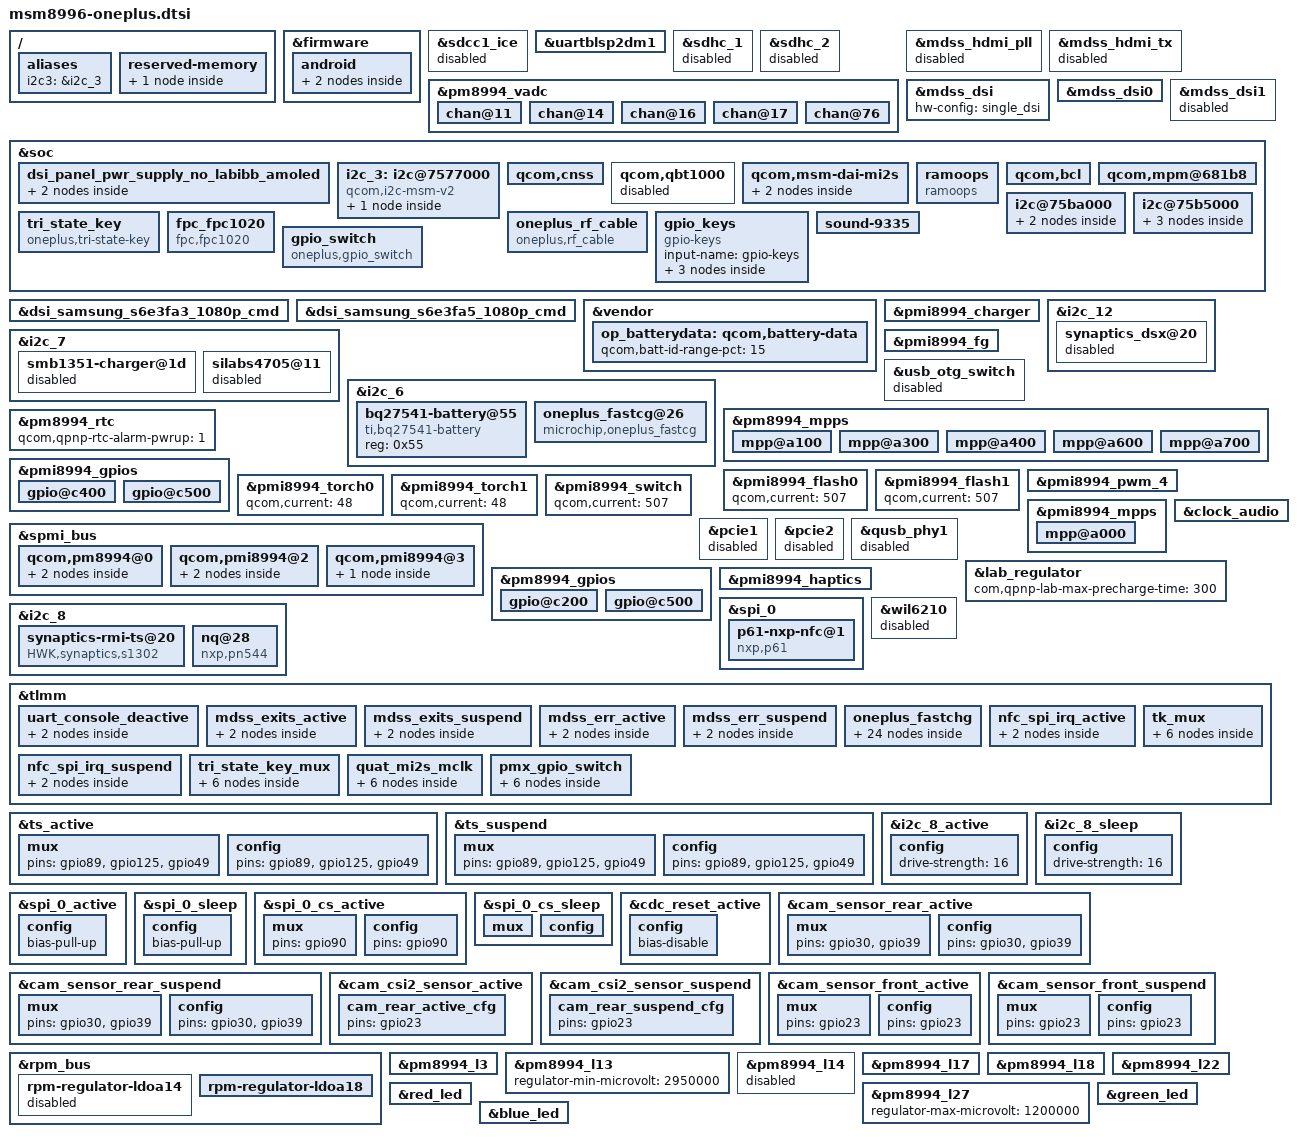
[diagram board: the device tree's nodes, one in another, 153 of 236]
/* Copyright (c) 2015-2016, The Linux Foundation. All rights reserved.
 *
 * This program is free software; you can redistribute it and/or modify
 * it under the terms of the GNU General Public License version 2 and
 * only version 2 as published by the Free Software Foundation.
 *
 * This program is distributed in the hope that it will be useful,
 * but WITHOUT ANY WARRANTY; without even the implied warranty of
 * MERCHANTABILITY or FITNESS FOR A PARTICULAR PURPOSE.  See the
 * GNU General Public License for more details.
 */

#include "dsi-panel-samsung-s6e3fa3-1080p-cmd.dtsi"
#include "dsi-panel-samsung-s6e3fa5-1080p-cmd.dtsi"

/ {
	aliases {
		i2c3 = &i2c_3;
	};

	reserved-memory {
		ramoops_mem: ramoops_region@ac000000 {
			compatible = "removed-dma-pool";
			no-map;
			reg = <0 0xAC000000 0 0x200000>;
		};
	};
};

&firmware {
	android {
		fstab {
			/delete-node/ vendor;
			system {
				compatible = "android,system";
				dev = "/dev/block/platform/soc/624000.ufshc/by-name/system";
				type = "ext4";
				mnt_flags = "ro,barrier=1,discard";
				fsmgr_flags = "wait,verify";
				status = "ok";
			};
		};
	};
};

&sdcc1_ice {
	status = "disabled";
};

&uartblsp2dm1 {
	status = "ok";
	pinctrl-names = "uart_active", "uart_deactive";
	pinctrl-0 = <&uart_console_active>;
	pinctrl-1 = <&uart_console_deactive>;
};

&sdhc_1 {
	status = "disabled";
};

&sdhc_2 {
	status = "disabled";
};

&pm8994_vadc {
	/* VADC Channel configuration */
	chan@11 {
		label = "rf_mpp2";
		reg = <0x11>;
		qcom,decimation = <0>;
		qcom,pre-div-channel-scaling = <0>;
		qcom,calibration-type = "absolute";
		qcom,scale-function = <0>;
		qcom,hw-settle-time = <0>;
		qcom,fast-avg-setup = <0>;
	};
	chan@14 {
		label = "rf_mpp5";
		reg = <0x14>;
		qcom,decimation = <0>;
		qcom,pre-div-channel-scaling = <0>;
		qcom,calibration-type = "absolute";
		qcom,scale-function = <0>;
		qcom,hw-settle-time = <0>;
		qcom,fast-avg-setup = <0>;
	};
	chan@16 {
		label = "id_ant_pcba_mpp7";
		reg = <0x16>;
		qcom,decimation = <0>;
		qcom,pre-div-channel-scaling = <0>;
		qcom,calibration-type = "absolute";
		qcom,scale-function = <0>;
		qcom,hw-settle-time = <0>;
		qcom,fast-avg-setup = <0>;
	};
	chan@17 {
		label = "rf_mpp8";
		reg = <0x17>;
		qcom,decimation = <0>;
		qcom,pre-div-channel-scaling = <0>;
		qcom,calibration-type = "absolute";
		qcom,scale-function = <0>;
		qcom,hw-settle-time = <0>;
		qcom,fast-avg-setup = <0>;
	};
	chan@76 {
		label = "pcb_version_AMUX_HW_ID";
		reg = <0x76>;
		qcom,decimation = <0>;
		qcom,pre-div-channel-scaling = <0>;
		qcom,calibration-type = "absolute";
		qcom,scale-function = <0>;
		qcom,hw-settle-time = <0>;
		qcom,fast-avg-setup = <0>;
	};
};

&mdss_hdmi_pll {
	status = "disabled";
};

&mdss_hdmi_tx {
	status = "disabled";
};

&mdss_dsi {
	hw-config = "single_dsi";
};

&mdss_dsi0 {
	qcom,dsi-pref-prim-pan = <&dsi_samsung_s6e3fa3_1080p_cmd>;
	pinctrl-names = "mdss_default", "mdss_sleep";
	pinctrl-0 = <&mdss_dsi_active &mdss_te_active &mdss_exits_active &mdss_err_active>;
	pinctrl-1 = <&mdss_dsi_suspend &mdss_te_suspend &mdss_exits_suspend &mdss_err_suspend>;
	qcom,platform-te-gpio = <&tlmm 11 0>;
	qcom,platform-reset-gpio = <&tlmm 8 0>;
	qcom,lcd-vddi-en-gpio = <&tlmm 26 0>;
	oled-vdda-supply = <&pm8994_s5>;
	vddio-supply = <&pm8994_l18>;
	/delete-property/ qcom,platform-reset-gpio;
	/delete-property/ qcom,platform-bklight-en-gpio;
	/delete-property/ lab-supply;
	/delete-property/ ibb-supply;
};

&mdss_dsi1 {
	status = "disabled";
};

&soc {
	dsi_panel_pwr_supply_no_labibb_amoled: dsi_panel_pwr_supply_no_labibb_amoled {
		#address-cells = <1>;
		#size-cells = <0>;

		qcom,panel-supply-entry@0 {
			reg = <0>;
			qcom,supply-name = "vddio";
			qcom,supply-min-voltage = <3300000>;
			qcom,supply-max-voltage = <3300000>;
			qcom,supply-enable-load = <62000>;
			qcom,supply-disable-load = <80>;
		};

		qcom,panel-supply-entry@1 {
			reg = <1>;
			qcom,supply-name = "oled-vdda";
			qcom,supply-min-voltage = <2150000>;
			qcom,supply-max-voltage = <2150000>;
			qcom,supply-enable-load = <62000>;
			qcom,supply-disable-load = <0>;
		};
	};
};

&dsi_samsung_s6e3fa3_1080p_cmd {
	qcom,mdss-dsi-panel-timings-phy-v2 = [
		24 1F 08 09 05 03 04 a0
		24 1F 08 09 05 03 04 a0
		24 1F 08 09 05 03 04 a0
		24 1F 08 09 05 03 04 a0
		24 1B 08 09 05 03 04 a0
	];
	qcom,cont-splash-enabled;
	qcom,panel-supply-entries = <&dsi_panel_pwr_supply_no_labibb_amoled>;
	qcom,esd-check-enabled;
	qcom,mdss-dsi-panel-status-check-mode = "te_signal_check";
	qcom,ulps-enabled;
	qcom,panel-allow-phy-poweroff;
};

&dsi_samsung_s6e3fa5_1080p_cmd {
       qcom,mdss-dsi-panel-timings-phy-v2  = [
		24 1F 08 09 05 03 04 a0
		24 1F 08 09 05 03 04 a0
		24 1F 08 09 05 03 04 a0
		24 1F 08 09 05 03 04 a0
		24 1B 08 09 05 03 04 a0
	];
	qcom,cont-splash-enabled;
	qcom,panel-supply-entries = <&dsi_panel_pwr_supply_no_labibb_amoled>;
	qcom,esd-check-enabled;
	qcom,mdss-dsi-panel-status-check-mode = "te_signal_check";
	qcom,ulps-enabled;
	qcom,panel-allow-phy-poweroff;
};

&vendor {
	op_batterydata: qcom,battery-data {
		qcom,batt-id-range-pct = <15>;
		#include "batterydata-op-3000mah.dtsi"
		#include "batterydata-op-3400mah.dtsi"
	};
};

&pmi8994_charger {
	qcom,iterm-ma = <200>;
	qcom,float-voltage-mv = <4320>;
	qcom,override-usb-current;
	/* ibatmax setting for different temp regions */
	qcom,ibatmax-little-cold-ma = <300>;
	qcom,ibatmax-cool-ma = <400>;
	qcom,ibatmax-little-cool-ma = <700>;
	qcom,ibatmax-pre-normal-ma = <1200>;
	qcom,ibatmax-normal-ma = <1910>;
	qcom,ibatmax-warm-ma = <700>;
	/* vbatmax setting for different temp regions */
	qcom,vbatmax-little-cold-mv = <3980>;
	qcom,vbatmax-cool-mv = <4320>;
	qcom,vbatmax-little-cool-mv = <4320>;
	qcom,vbatmax-pre-normal-mv = <4320>;
	qcom,vbatmax-normal-mv = <4320>;
	qcom,vbatmax-warm-mv = <4080>;
	/* vbatdet setting for different temp regions */
	qcom,vbatdet-little-cold-mv = <3700>;
	qcom,vbatdet-cool-mv = <4100>;
	qcom,vbatdet-little-cool-mv = <4220>;
	qcom,vbatdet-pre-normal-mv = <4220>;
	qcom,vbatdet-normal-mv = <4220>;
	qcom,vbatdet-warm-mv = <4000>;
	/* vbatdet setting for different temp regions */
	qcom,cold-bat-decidegc = <30>;
	qcom,little-cold-bat-decidegc = <0>;
	qcom,cool-bat-decidegc = <50>;
	qcom,little-cool-bat-decidegc = <120>;
	qcom,pre-normal-bat-decidegc = <160>;
	qcom,warm-bat-decidegc = <450>;
	qcom,hot-bat-decidegc = <530>;
	qcom,cutoff-voltage-with-charger=<3250>;
	qcom,thermal-mitigation = <2000 1300 1200 1200>;
};

&i2c_7 {
	smb1351-charger@1d {
		status = "disabled";
	};
};

&i2c_12 {
	synaptics_dsx@20 {
		status = "disabled"; 
	};
};

&i2c_6 {
	qcom,clk-freq-out = <100000>;
	qcom,fs-clk-div =<104>;
	qcom,high-time-clk-div=<82>;
	bq27541-battery@55 {
		status = "ok";
		compatible = "ti,bq27541-battery";
		reg = <0x55>;
	};
	oneplus_fastcg@26{
		status = "ok";
		compatible = "microchip,oneplus_fastcg";
		reg = <0x26>;
		microchip,mcu-en-gpio = <&tlmm 119 0x00>;
		microchip,usb-sw-gpio = <&tlmm 135 0x00>;
		microchip,ap-clk = <&tlmm 75 0x00>;
		microchip,ap-data = <&tlmm 74 0x00>;
		pinctrl-names = "mux_fastchg_active",
				"mux_fastchg_suspend",
				"mcu_data_active",
				"mcu_data_suspend";
		pinctrl-0 = <&fastchg_active
		&usb_sw_active
		&ap_clk_active >;
		pinctrl-1 = <&usb_sw_suspend
		&fastchg_suspend
		&ap_clk_suspend>;
		pinctrl-2 =<&ap_data_active>;
		pinctrl-3 =<&ap_data_suspend>;
		clocks = <&clock_gcc clk_uart_snoc_msmbus_a_clk>,
			 <&clock_gcc clk_uart_cnoc_msmbus_a_clk>;
		clock-names = "snoc", "cnoc";

	};
};

&pmi8994_fg {
	qcom,battery-data = <&op_batterydata>;
	/delete-property/ qcom,ext-sense-type;
	qcom,resume-soc = <99>;
	qcom,fg-iterm-ma = <200>;
	qcom,fg-chg-iterm-ma = <165>;
	qcom,fg-cc-cv-threshold-mv = <4310>;
	qcom,fg-cutoff-voltage-mv=<3200>;
	oem,use_external_fg;
};

&usb_otg_switch {
	status = "disabled";
};

&pm8994_mpps {
	mpp@a100 { /* MPP 2 */
		qcom,mode = <4>; /* AIN input */
		qcom,ain-route = <1>; /* AMUX 6 ,QPNP_PIN_AIN_AMUX_CH6   = 1*/
		qcom,master-en = <1>; /* Enable MPP */
		qcom,src-sel = <0>; /* Function constant */
		/delete-property/ status;
	};

	mpp@a300 { /* MPP 4 */
		qcom,mode = <4>; /* AIN input */
		qcom,invert = <1>; /* Enable MPP */
		qcom,ain-route = <3>; /* AMUX 8 */
		qcom,master-en = <1>;
		qcom,src-sel = <0>; /* Function constant */
	};

	mpp@a400 { /* MPP 5 */
		qcom,mode = <4>; /* AIN input */
		qcom,ain-route = <0>; /* AMUX 5 ,QPNP_PIN_AIN_AMUX_CH5   = 0*/
		qcom,master-en = <1>; /* Enable MPP */
		qcom,src-sel = <0>; /* Function constant */
		/delete-property/ status;
	};

	mpp@a600 { /* MPP 7 */
		qcom,mode = <4>; /* AIN input */
		qcom,ain-route = <2>; /* AMUX 7 ,QPNP_PIN_AIN_AMUX_CH7   = 2*/
		qcom,master-en = <1>; /* Enable MPP */
		qcom,src-sel = <0>; /* Function constant */
		/delete-property/ status;
	};

	mpp@a700 { /* MPP 8 */
		qcom,mode = <4>; /* AIN input */
		qcom,ain-route = <3>; /* AMUX 6 ,QPNP_PIN_AIN_AMUX_CH8   = 3*/
		qcom,master-en = <1>; /* Enable MPP */
		qcom,src-sel = <0>; /* Function constant */
		/delete-property/ status;
	};
};

&pm8994_rtc {
	qcom,qpnp-rtc-alarm-pwrup = <1>;
};

&pmi8994_gpios {
	gpio@c400 {//pmi8996 gpio 5 type-c IC INT pin
		qcom,mode = <0>;
		qcom,pull = <5>;
		qcom,vin-sel = <2>;
		qcom,src-sel = <0>;
		qcom,master-en = <1>;
		status = "okay";

	};

	gpio@c500 {//pmi8996 gpio 6 type-c IC OTG_USB_ID pin
		qcom,mode = <0>;
		qcom,pull = <5>;
		qcom,vin-sel = <2>;
		qcom,src-sel = <0>;
		qcom,master-en = <1>;
		status = "okay";
	};
};

&pmi8994_flash0 {
	qcom,current = <507>;
};

&pmi8994_flash1 {
	qcom,current = <507>;
};

&pmi8994_pwm_4 {
	qcom,channel-owner = "lcd_bl";
	qcom,dtest-line = <4>;
	qcom,dtest-output = <1>;
	status = "okay";
};

&pmi8994_torch0 {
	qcom,current = <48>;
};

&pmi8994_torch1 {
	qcom,current = <48>;
};

&pmi8994_switch {
	qcom,current = <507>;
};

&pmi8994_mpps {
	mpp@a000 { /* MPP 1 */
		qcom,mode = <1>;                /* Digital output */
		qcom,output-type = <0>;         /* CMOS logic */
		qcom,vin-sel = <2>;             /* S4 1.8V */
		qcom,src-sel = <7>;             /* DTEST4 */
		qcom,master-en = <1>;           /* Enable MPP */
		status = "okay";
	};
	/delete-node/ mpp@a300;
};

&soc {
	i2c_3: i2c@7577000 { /* BLSP2 QUP1 */
			compatible = "qcom,i2c-msm-v2";
			#address-cells = <1>;
			#size-cells = <0>;
			reg-names = "qup_phys_addr";
			reg = <0x7577000 0x1000>;
			interrupt-names = "qup_irq";
			interrupts = <0 97 0>;
			dmas = <&dma_blsp1 16 32 0x20000020 0x20>,
			<&dma_blsp1 17 32 0x20000020 0x20>;
			dma-names = "tx", "rx";
			qcom,master-id = <86>;
			qcom,clk-freq-out = <100000>;
			qcom,clk-freq-in = <19200000>;
			qcom,fs-clk-div =<104>;
			qcom,high-time-clk-div=<82>;
			clock-names = "iface_clk", "core_clk";
			clocks = <&clock_gcc clk_gcc_blsp1_ahb_clk>,
			<&clock_gcc clk_gcc_blsp1_qup3_i2c_apps_clk>;
			pinctrl-names = "i2c_active", "i2c_sleep";
			pinctrl-0 = <&i2c_3_active>;
			pinctrl-1 = <&i2c_3_sleep>;
	};

	qcom,cnss {
		/delete-property/ wlan-ant-switch-supply;
	};

	qcom,qbt1000 {
		status = "disabled";
	};

	qcom,msm-dai-mi2s {
		/delete-node/ qcom,msm-dai-q6-mi2s-tert;
		/delete-node/ qcom,msm-dai-q6-mi2s-quat;
		dai_tert_mi2s: qcom,msm-dai-q6-mi2s-tert {
				compatible = "qcom,msm-dai-q6-mi2s";
				qcom,msm-dai-q6-mi2s-dev-id = <2>;
				qcom,msm-mi2s-rx-lines = <2>;
				qcom,msm-mi2s-tx-lines = <1>;
				pinctrl-names = "default", "sleep";
		};

		dai_quat_mi2s: qcom,msm-dai-q6-mi2s-quat {
			compatible = "qcom,msm-dai-q6-mi2s";
			qcom,msm-dai-q6-mi2s-dev-id = <3>;
			qcom,msm-mi2s-rx-lines = <1>; /* SD0 (1 << 0) */
			qcom,msm-mi2s-tx-lines = <2>; /* SD1 (1 << 1) */
			qcom,msm-mi2s-slave = <0>;
			qcom,msm-mi2s-ext-mclk = <0>;
			pinctrl-names = "default", "sleep";

			pinctrl-0 = <&quat_mi2s_active  &quat_mi2s_sd0_active &quat_mi2s_sd1_active >;
			pinctrl-1 = <&quat_mi2s_sleep  &quat_mi2s_sd0_sleep &quat_mi2s_sd1_sleep >;
		};
	};

	ramoops {
		compatible = "ramoops";
		memory-region = <&ramoops_mem>;
		record-size = <0x0 0x20000>;
		console-size = <0x0 0x100000>;
		pmsg-size = <0x0 0x80000>;
	};

	qcom,bcl {
		/delete-property/ qcom,bcl-hotplug-list;
		/delete-property/ qcom,bcl-soc-hotplug-list;
	};

	qcom,mpm@681b8 {
		qcom,gic-map = <2 216>, /* tsens_upper_lower_int */
			<79 379>,   /* qusb2phy_dmse_hv_prim */
			<80 384>,   /* qusb2phy_dmse_hv_sec */
			<81 379>,   /* qusb2phy_dpse_hv_prim */
			<82 384>,   /* qusb2phy_dpse_hv_sec */
			<52 275>,   /* qmp_usb3_lfps_rxterm_irq */
			<87 358>,   /* ee0_krait_hlos_spmi_periph_irq */
			<0xff 16>,  /* APCj_qgicdrCpu0HwFaultIrptReq */
			<0xff 23>,  /* APCj_qgicdrCpu0PerfMonIrptReq */
			<0xff 27>,  /* APCj_qgicdrCpu0QTmrVirtIrptReq */
			<0xff 32>,  /* APCj_qgicdrL2PerfMonIrptReq */
			<0xff 33>,  /* APCC_qgicL2PerfMonIrptReq */
			<0xff 34>,  /* APCC_qgicL2ErrorIrptReq */
			<0xff 35>,  /* WDT_barkInt */
			<0xff 40>,  /* qtimer_phy_irq */
			<0xff 41>,  /* APCj_qgicdrL2HwFaultNonFatalIrptReq */
			<0xff 42>,  /* APCj_qgicdrL2HwFaultFatalIrptReq */
			<0xff 49>,  /* L3UX_qgicL3ErrorIrptReq */
			<0xff 54>,  /* M4M_sysErrorInterrupt */
			<0xff 55>,  /* M4M_sysDlmInterrupt */
			<0xff 57>,  /* mss_to_apps_irq(0) */
			<0xff 58>,  /* mss_to_apps_irq(1) */
			<0xff 59>,  /* mss_to_apps_irq(2) */
			<0xff 60>,  /* mss_to_apps_irq(3) */
			<0xff 61>,  /* mss_a2_bam_irq */
			<0xff 62>,  /* QTMR_qgicFrm0VirtIrq */
			<0xff 63>,  /* QTMR_qgicFrm1PhysIrq */
			<0xff 64>,  /* QTMR_qgicFrm2PhysIrq */
			<0xff 65>,  /* QTMR_qgicFrm3PhysIrq */
			<0xff 66>,  /* QTMR_qgicFrm4PhysIrq */
			<0xff 67>,  /* QTMR_qgicFrm5PhysIrq */
			<0xff 68>,  /* QTMR_qgicFrm6PhysIrq */
			<0xff 69>,  /* QTMR_qgicFrm7PhysIrq */
			<0xff 70>,  /* iommu_pmon_nonsecure_irq */
			<0xff 74>,  /* osmmu_CIrpt[1] */
			<0xff 75>,  /* osmmu_CIrpt[0] */
			<0xff 77>,  /* osmmu_CIrpt[0] */
			<0xff 78>,  /* osmmu_CIrpt[0] */
			<0xff 79>,  /* osmmu_CIrpt[0] */
			<0xff 80>,  /* CPR3_irq */
			<0xff 94>,  /* osmmu_CIrpt[0] */
			<0xff 97>,  /* iommu_nonsecure_irq */
			<0xff 99>,  /* msm_iommu_pmon_nonsecure_irq */
			<0xff 101>, /* camss_jpeg_mmu_cirpt */
			<0xff 102>, /* osmmu_CIrpt[1] */
			<0xff 105>, /* iommu_pmon_nonsecure_irq */
			<0xff 108>, /* osmmu_PMIrpt */
			<0xff 109>, /* ocmem_dm_nonsec_irq */
			<0xff 110>, /* csiphy_0_irq */
			<0xff 111>, /* csiphy_1_irq */
			<0xff 112>, /* csiphy_2_irq */
			<0xff 115>, /* mdss_irq */
			<0xff 126>, /* bam_irq[0] */
			<0xff 127>, /* blsp1_qup_irq(0) */
			<0xff 129>,
			<0xff 132>, /* blsp1_qup_irq(5) */
			<0xff 133>, /* blsp2_qup_irq(0) */
			<0xff 134>, /* blsp2_qup_irq(1) */
			<0xff 135>, /* blsp2_qup_irq(2) */
			<0xff 138>, /* blsp2_qup_irq(5) */
			<0xff 140>, /* blsp1_uart_irq(1) */
			<0xff 146>, /* blsp2_uart_irq(1) */
			<0xff 155>, /* sdcc_irq[0] */
			<0xff 157>, /* sdc2_irq[0] */
			<0xff 163>, /* usb30_ee1_irq */
			<0xff 164>, /* usb30_bam_irq(0) */
			<0xff 165>, /* usb30_hs_phy_irq */
			<0xff 166>, /* sdc1_pwr_cmd_irq */
			<0xff 170>, /* sdcc_pwr_cmd_irq */
			<0xff 171>, /* usb20_hs_phy_irq */
			<0xff 172>, /* usb20_power_event_irq */
			<0xff 173>, /* sdc1_irq[0] */
			<0xff 174>, /* o_wcss_apss_smd_med */
			<0xff 175>, /* o_wcss_apss_smd_low */
			<0xff 176>, /* o_wcss_apss_smsm_irq */
			<0xff 177>, /* o_wcss_apss_wlan_data_xfer_done */
			<0xff 178>, /* o_wcss_apss_wlan_rx_data_avail */
			<0xff 179>, /* o_wcss_apss_asic_intr */
			<0xff 180>, /* pcie20_2_int_pls_err */
			<0xff 181>, /* wcnss watchdog */
			<0xff 188>, /* lpass_irq_out_apcs(0) */
			<0xff 189>, /* lpass_irq_out_apcs(1) */
			<0xff 190>, /* lpass_irq_out_apcs(2) */
			<0xff 191>, /* lpass_irq_out_apcs(3) */
			<0xff 192>, /* lpass_irq_out_apcs(4) */
			<0xff 193>, /* lpass_irq_out_apcs(5) */
			<0xff 194>, /* lpass_irq_out_apcs(6) */
			<0xff 195>, /* lpass_irq_out_apcs(7) */
			<0xff 196>, /* lpass_irq_out_apcs(8) */
			<0xff 197>, /* lpass_irq_out_apcs(9) */
			<0xff 198>, /* coresight-tmc-etr interrupt */
			<0xff 200>, /* rpm_ipc(4) */
			<0xff 201>, /* rpm_ipc(5) */
			<0xff 202>, /* rpm_ipc(6) */
			<0xff 203>, /* rpm_ipc(7) */
			<0xff 204>, /* rpm_ipc(24) */
			<0xff 205>, /* rpm_ipc(25) */
			<0xff 206>, /* rpm_ipc(26) */
			<0xff 207>, /* rpm_ipc(27) */
			<0xff 208>,
			<0xff 210>,
			<0xff 211>, /* usb_dwc3_otg */
			<0xff 212>, /* usb30_power_event_irq */
			<0xff 215>, /* o_bimc_intr(0) */
			<0xff 224>, /* spdm_realtime_irq[1] */
			<0xff 238>, /* crypto_bam_irq[0] */
			<0xff 240>, /* summary_irq_kpss */
			<0xff 253>, /* sdc2_pwr_cmd_irq */
			<0xff 258>, /* lpass_irq_out_apcs[21] */
			<0xff 268>, /* bam_irq[1] */
			<0xff 270>, /* bam_irq[0] */
			<0xff 271>, /* bam_irq[0] */
			<0xff 276>, /* wlan_pci */
			<0xff 283>, /* pcie20_0_int_pls_err */
			<0xff 284>, /* pcie20_0_int_aer_legacy */
			<0xff 286>, /* pcie20_0_int_pls_link_down */
			<0xff 290>, /* ufs_ice_nonsec_level_irq */
			<0xff 293>, /* pcie20_2_int_pls_link_down */
			<0xff 295>, /* camss_cpp_mmu_cirpt[0] */
			<0xff 296>, /* camss_cpp_mmu_pmirpt */
			<0xff 297>, /* ufs_intrq */
			<0xff 298>, /* camss_cpp_mmu_cirpt */
			<0xff 302>, /* qdss_etrbytecnt_irq */
			<0xff 310>, /* pcie20_1_int_pls_err */
			<0xff 311>, /* pcie20_1_int_aer_legacy */
			<0xff 313>, /* pcie20_1_int_pls_link_down */
			<0xff 318>, /* venus0_mmu_pmirpt */
			<0xff 319>, /* venus0_irq */
			<0xff 325>, /* camss_irq18 */
			<0xff 326>, /* camss_irq0 */
			<0xff 327>, /* camss_irq1 */
			<0xff 328>, /* camss_irq2 */
			<0xff 329>, /* camss_irq3 */
			<0xff 330>, /* camss_irq4 */
			<0xff 331>, /* camss_irq5 */
			<0xff 332>, /* sps */
			<0xff 336>,
			<0xff 341>, /* camss_irq6 */
			<0xff 346>, /* camss_irq8 */
			<0xff 347>, /* camss_irq9 */
			<0xff 348>,
			<0xff 352>, /* mdss_mmu_cirpt[0] */
			<0xff 353>, /* mdss_mmu_cirpt[1] */
			<0xff 361>, /* ogpu_mmu_cirpt[0] */
			<0xff 362>, /* ogpu_mmu_cirpt[1] */
			<0xff 365>, /* ipa_irq[0] */
			<0xff 366>, /* ogpu_mmu_pmirpt */
			<0xff 367>, /* venus0_mmu_cirpt[0] */
			<0xff 368>, /* venus0_mmu_cirpt[1] */
			<0xff 369>, /* venus0_mmu_cirpt[2] */
			<0xff 370>, /* venus0_mmu_cirpt[3] */
			<0xff 375>, /* camss_vfe_mmu_cirpt[0] */
			<0xff 376>, /* camss_vfe_mmu_cirpt[1] */
			<0xff 380>, /* mdss_dma_mmu_cirpt[0] */
			<0xff 381>, /* mdss_dma_mmu_cirpt[1] */
			<0xff 385>, /* mdss_dma_mmu_pmirpt */
			<0xff 387>, /* osmmu_CIrpt[0] */
			<0xff 394>, /* osmmu_PMIrpt */
			<0xff 403>, /* osmmu_PMIrpt */
			<0xff 405>, /* osmmu_CIrpt[0] */
			<0xff 413>, /* osmmu_PMIrpt */
			<0xff 422>, /* ssc_irq_out_apcs[5] */
			<0xff 424>, /* ipa_irq[2] */
			<0xff 425>, /* lpass_irq_out_apcs[22] */
			<0xff 426>, /* lpass_irq_out_apcs[23] */
			<0xff 427>, /* lpass_irq_out_apcs[24] */
			<0xff 428>, /* lpass_irq_out_apcs[25] */
			<0xff 429>, /* lpass_irq_out_apcs[26] */
			<0xff 430>, /* lpass_irq_out_apcs[27] */
			<0xff 431>, /* lpass_irq_out_apcs[28] */
			<0xff 432>, /* lpass_irq_out_apcs[29] */
			<0xff 436>, /* lpass_irq_out_apcs[37] */
			<0xff 437>, /* pcie20_0_int_msi_dev0 */
			<0xff 445>, /* pcie20_1_int_msi_dev0 */
			<0xff 453>, /* pcie20_2_int_msi_dev0 */
			<0xff 461>, /* o_vmem_nonsec_irq */
			<0xff 462>, /* tsens1_tsens_critical_int */
			<0xff 464>, /* ipa_bam_irq[0] */
			<0xff 465>, /* ipa_bam_irq[2] */
			<0xff 477>, /* tsens0_tsens_critical_int */
			<0xff 480>, /* q6_wdog_expired_irq */
			<0xff 481>, /* mss_ipc_out_irq(4) */
			<0xff 483>, /* mss_ipc_out_irq(6) */
			<0xff 484>, /* mss_ipc_out_irq(7) */
			<0xff 487>, /* mss_ipc_out_irq(30) */
			<0xff 490>, /* tsens0_tsens_upper_lower_int */
			<0xff 493>; /* sdc1_ice_nonsec_level_irq */
		qcom,gpio-map = <3  1>,
			<4  5>,
			<5  9>,
			<6  11>,
			<7  66>,
			<8  22>,
			<9  24>,
			<10  26>,
			<11  34>,
			<12  36>,
			<13  37>, /* PCIe0 */
			<14  38>,
			<15  40>,
			<16  42>,
			<17  46>,
			<18  50>,
			<19  53>,
			<20  54>,
			<21  56>,
			<22  57>,
			<23  58>,
			<24  59>,
			<25  60>,
			<26  61>,
			<27  62>,
			<28  63>,
			<29  64>,
			<30  71>,
			<31  73>,
			<0xff  74>,
			<32  77>,
			<33  78>,
			<34  79>,
			<35  80>,
			<36  82>,
			<37  86>,
			<38  91>,
			<39  92>,
			<40  95>,
			<41  97>,
			<42  101>,
			<43  104>,
			<44  106>,
			<45  108>,
			<46  112>,
			<47  113>,
			<48  110>,
			<50  127>,
			<51  115>,
			<54  116>, /* PCIe2 */
			<55  117>,
			<56  118>,
			<57  119>,
			<58  120>,
			<59  121>,
			<60  122>,
			<61  123>,
			<62  124>,
			<63  125>,
			<64  126>,
			<65  129>,
			<66  131>,
			<67  132>, /* PCIe1 */
			<68  133>,
			<69  145>;
	};

	i2c@75ba000 {
		synaptics@20 {
			status = "disabled";
		};
		synaptics-rmi-ts@20 {
			compatible = "synaptics,s3320";
			reg = <0x20>;
			interrupt-parent = <&tlmm>;
			interrupts = <125 0x2008>;
			synaptics,irq-gpio = <&tlmm 125 0x2008>;
			synaptics,reset-gpio = <&tlmm 89 0x00>;
			synaptics,1v8-gpio = <&tlmm 49 0x00>;
			synaptics,tx-rx-num = <16 28>;
			synaptics,display-coords = <1080 1920>;
			vdd_2v8-supply = <&pm8994_l22>;
			vcc_i2c_1v8-supply = <&pm8994_s4>;
			oem,support_hw_poweroff;
			pinctrl-names = "pmx_ts_active", "pmx_ts_suspend";
			pinctrl-0 = <&ts_active>;
			pinctrl-1 = <&ts_suspend>;
		};
	};

	i2c@75b5000 {
		fusb301@21 {
			compatible = "fusb301";
			reg = <0x21>;
			fusb301,ID-gpio = <&pmi8994_gpios 6 0>;
			fusb301,irq-gpio = <&pmi8994_gpios 5 0>;
			// Underlying clocks used by secure touch
			clock-names = "iface_clk", "core_clk";
			clocks = <&clock_gcc clk_gcc_blsp2_ahb_clk>,
				 <&clock_gcc clk_gcc_blsp2_qup1_i2c_apps_clk>;
		};
		tusb320@60 {
			compatible = "tusb320";
			reg = <0x60>;
			tusb320,ID-gpio = <&pmi8994_gpios 6 0>;
			tusb320,irq-gpio = <&pmi8994_gpios 5 0>;
			// Underlying clocks used by secure touch
			clock-names = "iface_clk", "core_clk";
			clocks = <&clock_gcc clk_gcc_blsp2_ahb_clk>,
				 <&clock_gcc clk_gcc_blsp2_qup1_i2c_apps_clk>;
		};

		ptn5150@1d {
			compatible = "ptn5150";
			reg = <0x1d>;
			ptn5150,ID-gpio = <&pmi8994_gpios 6 0>;
			ptn5150,irq-gpio = <&pmi8994_gpios 5 0>;
			// Underlying clocks used by secure touch
			clock-names = "iface_clk", "core_clk";
			clocks = <&clock_gcc clk_gcc_blsp2_ahb_clk>,
				 <&clock_gcc clk_gcc_blsp2_qup1_i2c_apps_clk>;
		};

	};

	tri_state_key {
		compatible = "oneplus,tri-state-key";
		interrupt-parent = <&tlmm>;
		tristate,gpio_key2 = <&pm8994_gpios 4 0>;
		tristate,gpio_key1 = <&pm8994_gpios 6 0>;
		tristate,gpio_key3 = <&pm8994_gpios 5 0>;

		#pinctrl-names = "pmx_tri_state_key_active", "pmx_tri_state_key_suspend";
		#pinctrl-0 = <&tri_state_key_active>;
		#pinctrl-1 = <&tri_state_key_suspend>;
	};

	fpc_fpc1020 {
		compatible = "fpc,fpc1020";
		interrupt-parent = <&tlmm>;
		fpc,reset-gpio    = <&tlmm 86 0>;
		fpc,irq-gpio    = <&tlmm 95 0>;
		fpc,gpio_id0    = <&tlmm 25 0>;
		fpc,gpio_id1    = <&tlmm 143 0>;
		fpc,gpio_1V8_EN = <&tlmm 14 0x00>;
		#vcc_spi-supply  = <&pm8994_l13>;
		#vdd_ana-supply  = <&pm8994_l13>;
		#vdd_io-supply   = <&pm8994_s4>;

		#pinctrl-names = "pmx_tri_state_key_active", "pmx_tri_state_key_suspend";
		#pinctrl-0 = <&tri_state_key_active>;
		#pinctrl-1 = <&tri_state_key_suspend>;
	};

	oneplus_rf_cable {
		compatible = "oneplus,rf_cable";
		interrupt-parent = <&tlmm>;
		rf,cable-gpio    = <&tlmm 131 0>;

		#pinctrl-names = "pmx_tri_state_key_active", "pmx_tri_state_key_suspend";
		#pinctrl-0 = <&tri_state_key_active>;
		#pinctrl-1 = <&tri_state_key_suspend>;
	};

	i2c@7577000{
		status = "ok";
		test_tfa9890: tfa9890@36 {
			compatible = "nxp,tfa9890";
			reg = <0x36>;
			reset_gpio= <&tlmm 16 0>;
			status = "okay";
		};
	};

	gpio_keys {
		compatible = "gpio-keys";
		input-name = "gpio-keys";

		vol_up {
			label = "volume_up";
			gpios = <&pm8994_gpios 3 0x1>;
			linux,input-type = <1>;
			linux,code = <115>;
			debounce-interval = <15>;
		};

		/delete-node/ cam_snapshot;
		/delete-node/ cam_focus;

		vol_down {
			label = "volume_down";
			gpios = <&pm8994_gpios 2 0x1>;
			linux,input-type = <1>;
			linux,code = <114>;
			debounce-interval = <15>;
		};

		hallsensor_key {
			label = "hallsensor_key";
			gpios = <&tlmm 124 1>;
			interrupt-parent = <&tlmm>;
			interrupts = <124 0x0>;
			linux,input-type = <5>;
			linux,code = <0>;
			gpio-key,wakeup;
			debounce-interval = <15>;
		};
	};

	sound-9335 {
		qcom,model = "msm8996-tasha-mtp-snd-card";

		qcom,audio-routing =
			"AIF4 VI", "MCLK",
			"RX_BIAS", "MCLK",
			"MADINPUT", "MCLK",
			"hifi amp", "LINEOUT1",
			"hifi amp", "LINEOUT2",
			"AMIC2", "MIC BIAS2",
			"MIC BIAS2", "Headset Mic",
			"AMIC4", "MIC BIAS1",
			"MIC BIAS1", "Primary Mic",
			"AMIC5", "MIC BIAS3",
			"MIC BIAS3", "Noise Mic";

		qcom,tdm-audio-intf;
		/delete-property/ qcom,hdmi-audio-rx;
		asoc-codec = <&stub_codec>,<&test_tfa9890>;
		asoc-codec-names = "msm-stub-codec.1","tfa98xx.3-0036";
		/delete-property/ qcom,hph-en1-gpio;
		/delete-property/ qcom,hph-en0-gpio;
		qcom,msm-mbhc-hphl-swh = <1>;
		qcom,msm-mbhc-gnd-swh = <1>;
		/delete-property/ qcom,us-euro-gpios;
		/delete-property/ qcom,wsa-max-devs;
		/delete-property/ qcom,wsa-devs;
		/delete-property/ qcom,wsa-aux-dev-prefix;
		asoc-cpu = <&dai_pri_auxpcm>, <&dai_sec_auxpcm>,
				<&dai_hdmi>, <&dai_tert_mi2s>, <&dai_quat_mi2s>,
				<&sb_0_rx>, <&sb_0_tx>,
				<&sb_1_rx>, <&sb_1_tx>,
				<&sb_2_rx>, <&sb_2_tx>,
				<&sb_3_rx>, <&sb_3_tx>,
				<&sb_4_rx>, <&sb_4_tx>,
				<&sb_5_tx>,
				<&afe_pcm_rx>, <&afe_pcm_tx>,
				<&afe_proxy_rx>, <&afe_proxy_tx>,
				<&incall_record_rx>, <&incall_record_tx>,
				<&incall_music_rx>, <&incall_music2_rx>,
				<&sb_5_rx>, <&sb_6_rx>,
				<&usb_audio_rx>, <&usb_audio_tx>,
				<&dai_pri_tdm_tx_0>, <&dai_pri_tdm_tx_1>,
				<&dai_pri_tdm_tx_2>, <&dai_pri_tdm_tx_3>,
				<&dai_pri_tdm_rx_0>, <&dai_pri_tdm_rx_1>,
				<&dai_pri_tdm_rx_2>, <&dai_pri_tdm_rx_3>,
				<&dai_sec_tdm_rx_0>, <&dai_sec_tdm_rx_1>,
				<&dai_sec_tdm_rx_2>, <&dai_sec_tdm_rx_3>,
				<&dai_sec_tdm_tx_0>, <&dai_sec_tdm_tx_1>,
				<&dai_sec_tdm_tx_2>, <&dai_sec_tdm_tx_3>,
				<&dai_tert_tdm_rx_0>, <&dai_tert_tdm_rx_1>,
				<&dai_tert_tdm_rx_2>, <&dai_tert_tdm_rx_3>,
				<&dai_tert_tdm_tx_0>, <&dai_tert_tdm_tx_1>,
				<&dai_tert_tdm_tx_2>, <&dai_tert_tdm_tx_3>,
				<&dai_quat_tdm_rx_0>, <&dai_quat_tdm_rx_1>,
				<&dai_quat_tdm_rx_2>, <&dai_quat_tdm_rx_3>,
				<&dai_quat_tdm_tx_0>, <&dai_quat_tdm_tx_1>,
				<&dai_quat_tdm_tx_2>, <&dai_quat_tdm_tx_3>;
		asoc-cpu-names = "msm-dai-q6-auxpcm.1", "msm-dai-q6-auxpcm.2",
				"msm-dai-q6-hdmi.8", "msm-dai-q6-mi2s.2","msm-dai-q6-mi2s.3",
				"msm-dai-q6-dev.16384", "msm-dai-q6-dev.16385",
				"msm-dai-q6-dev.16386", "msm-dai-q6-dev.16387",
				"msm-dai-q6-dev.16388", "msm-dai-q6-dev.16389",
				"msm-dai-q6-dev.16390", "msm-dai-q6-dev.16391",
				"msm-dai-q6-dev.16392", "msm-dai-q6-dev.16393",
				"msm-dai-q6-dev.16395",
				"msm-dai-q6-dev.224", "msm-dai-q6-dev.225",
				"msm-dai-q6-dev.241", "msm-dai-q6-dev.240",
				"msm-dai-q6-dev.32771", "msm-dai-q6-dev.32772",
				"msm-dai-q6-dev.32773", "msm-dai-q6-dev.32770",
				"msm-dai-q6-dev.16394", "msm-dai-q6-dev.16396",
				"msm-dai-q6-dev.28672", "msm-dai-q6-dev.28673",
				"msm-dai-q6-tdm.36865", "msm-dai-q6-tdm.36867",
				"msm-dai-q6-tdm.36869", "msm-dai-q6-tdm.36871",
				"msm-dai-q6-tdm.36864", "msm-dai-q6-tdm.36866",
				"msm-dai-q6-tdm.36868", "msm-dai-q6-tdm.36870",
				"msm-dai-q6-tdm.36880", "msm-dai-q6-tdm.36882",
				"msm-dai-q6-tdm.36884", "msm-dai-q6-tdm.36886",
				"msm-dai-q6-tdm.36881", "msm-dai-q6-tdm.36883",
				"msm-dai-q6-tdm.36885", "msm-dai-q6-tdm.36887",
				"msm-dai-q6-tdm.36896", "msm-dai-q6-tdm.36898",
				"msm-dai-q6-tdm.36900", "msm-dai-q6-tdm.36902",
				"msm-dai-q6-tdm.36897", "msm-dai-q6-tdm.36899",
				"msm-dai-q6-tdm.36901", "msm-dai-q6-tdm.36903",
				"msm-dai-q6-tdm.36912", "msm-dai-q6-tdm.36914",
				"msm-dai-q6-tdm.36916", "msm-dai-q6-tdm.36918",
				"msm-dai-q6-tdm.36913", "msm-dai-q6-tdm.36915",
				"msm-dai-q6-tdm.36917", "msm-dai-q6-tdm.36919";
	};

	gpio_switch {
		compatible = "oneplus,gpio_switch";
		gpios = <&tlmm  97 0x00>,
			<&tlmm  98 0x00>,
			<&tlmm 100 0x00>,
			<&tlmm 115 0x00>,
			<&tlmm 127 0x00>,
			<&tlmm 133 0x00>,
			<&tlmm 136 0x00>;
		pinctrl-names = "gpio_switch_pin_active", "gpio_switch_pin_suspend";
		pinctrl-0 = <&pmx_gpio_switch_pin_active>;
		pinctrl-1 = <&pmx_gpio_switch_pin_suspend>;
	};
};

&clock_audio {
	/delete-property/ pinctrl-0;
	/delete-property/ pinctrl-1;
};

&pcie1 {
	status = "disabled";
};

&pcie2 {
	status = "disabled";
};

&qusb_phy1 {
	status = "disabled";
};

&spmi_bus {
	qcom,pm8994@0 {
		qcom,power-on@800 {
			qcom,pon_1 {
				qcom,s2-type = <7>;
			};
			/delete-node/ qcom,pon_2;
			/delete-node/ qcom,pon_3;
		};
	};

	qcom,pmi8994@2 {
		qcom,leds@a300 {
			compatible = "qcom,leds-qpnp";
			status = "okay";
			reg=<0xa300 0x100>;
			qcom,led_mpp_4 {
				label = "mpp";
				linux,name = "button-backlight";
				linux,default-trigger = "none";
				qcom,default-state = "off";
				qcom,max-current = <40>;
				qcom,current-setting = <5>;
				qcom,id = <6>;
				qcom,mode = "manual";
				qcom,source-sel = <1>;
				qcom,mode-ctrl = <0x60>;
			};
		};
	};

	qcom,pmi8994@3 {
		qcom,leds@d000 {
			qcom,rgb-sync;
		};
	};
};

&lab_regulator {
	com,qpnp-lab-max-precharge-time = <300>;
};

&pm8994_gpios {
	gpio@c200 { /* GPIO 3 */
		qcom,mode = <0>;
		qcom,pull = <0>;
		qcom,vin-sel = <2>;
		qcom,src-sel = <0>;
		status = "okay";
	};

	gpio@c500 { /* GPIO 6 */
		qcom,mode = <0>;
		qcom,pull = <0>;
		qcom,vin-sel = <2>;
		qcom,src-sel = <0>;
		status = "okay";
	};
};

&pmi8994_haptics {
	qcom,actuator-type = <1>;
	qcom,vmax-mv = <2700>;
};

&i2c_7 {
	silabs4705@11 {
		status = "disabled";
	};
};

&i2c_8 { /* BLSP2 QUP2 */
	synaptics-rmi-ts@20 {
		compatible = "HWK,synaptics,s1302";
		reg = <0x20>;
		interrupt-parent = <&tlmm>;
		interrupts = <132 0x2008>;
		synaptics,irq-gpio = <&tlmm 132 0x2008>;
		synaptics,reset-gpio = <&tlmm 76 0x00>;
		vdd_2v8-supply = <&pm8994_l13>;
		vcc_i2c_1v8-supply = <&pm8994_s4>;
		oem,cover_reject;//when esd test cover the phone on the panel don't report keys;

		pinctrl-names = "pmx_tk_active", "pmx_tk_suspend";
		pinctrl-0 = <&tk_active>;
		pinctrl-1 = <&tk_suspend>;
	};
	nq@28 {
		compatible = "nxp,pn544";
		reg = <0x28>;
		nxp,pn544-irq = <&tlmm 9 0x00>;
		nxp,pn544-ven = <&tlmm 94 0x00>;
		nxp,pn544-fw-dwnld = <&tlmm 12 0x00>;
		nxp,pn544-ese-pwr = <&pm8994_gpios 07 0x00>;
		nxp,pn544-clk-gpio = <&pm8994_gpios 10 0x00>;
		interrupt-parent = <&tlmm>;
		qcom,clk-src = "BBCLK2";
		interrupts = <9 0>;
		interrupt-names = "nfc_irq";
		clocks = <&clock_gcc clk_bb_clk2_pin>;
		clock-names = "ref_clk";
		nfc_voltage_s4-supply = <&pm8994_s4>;
	};
};

&spi_0 { /* BLSP1 QUP1 */
	p61-nxp-nfc@1 { //Slave driver and CS ID
		compatible = "nxp,p61"; //Manufacture, and Model
		reg = <1>; //Same as CS ID
		nxp,p61-irq = <&tlmm 34 0x00>; //Pass a GPIO
		nxp,p61-rst = <&tlmm 21 0x00>; //Pass a GPIO
		spi-max-frequency = <19200000>;
		spi-cs-high; //CS Active High
		interrupt-parent = <&tlmm>; //GPIO Handler
		interrupts = <34 0>; //GPIO # and flags
	};
};

&wil6210 {
	status = "disabled";
};

&tlmm {
	uart_console_deactive: uart_console_deactive {
		mux {
			pins = "gpio4", "gpio5";
			function = "gpio";
		};

		config {
			pins = "gpio4", "gpio5";
			drive-strength = <2>;
			bias-disable;
		};
	};

	mdss_exits_active: mdss_exits_active {
		mux {
			pins = "gpio33";
			function = "gpio";
		};
		config {
			pins = "gpio33";
			drive-strength = <2>; /* 8 mA */
			bias-pull-down; /* pull down*/
		};
	};


	mdss_exits_suspend: mdss_exits_suspend {
		mux {
			pins = "gpio33";
			function = "gpio";
		};
		config {
			pins = "gpio33";
			drive-strength = <2>; /* 2 mA */
			bias-pull-down; /* pull down */
		};
	};

	mdss_err_active: mdss_err_active {
		mux {
			pins = "gpio24";
			function = "gpio";
		};
		config {
			pins = "gpio24";
			drive-strength = <2>; /* 8 mA */
			bias-pull-down; /* pull down*/
		};
	};


	mdss_err_suspend: mdss_err_suspend {
		mux {
			pins = "gpio24";
			function = "gpio";
		};
		config {
			pins = "gpio24";
			drive-strength = <2>; /* 2 mA */
			bias-pull-down; /* pull down */
		};
	};

	oneplus_fastchg {
		fastchg_active: fastchg_active {
			mux {
				pins = "gpio119";
				function = "gpio";
			};

			config {
				pins = "gpio119";
				drive-strength = <16>;
				bias-pull-up;
			};
		};

		fastchg_suspend: fastchg_suspend {
			mux {
				pins = "gpio119";
				function = "gpio";
			};

			config {
				pins = "gpio119";
				drive-strength = <2>;
				bias-disable;
			};
		};
		usb_sw_active: usb_sw_active {
			mux {
				pins = "gpio135";
				function = "gpio";
			};

			config {
				pins = "gpio135";
				drive-strength = <16>;
				bias-pull-up;
			};
		};
		ap_clk_suspend: ap_clk_suspend {
			mux {
				pins = "gpio75";
				function = "gpio";
			};

			config {
				pins = "gpio75";
				drive-strength = <2>;
				bias-disable;
			};
		};
		ap_clk_active: ap_clk_active {
			mux {
				pins = "gpio75";
				function = "gpio";
			};

			config {
				pins = "gpio75";
				drive-strength = <16>;
				bias-pull-up;
			};
		};
		ap_data_suspend: ap_data_suspend {
			mux {
				pins = "gpio74";
				function = "gpio";
			};

			config {
				pins = "gpio74";
				drive-strength = <2>;
				bias-disable;
			};
		};
		ap_data_active: ap_data_active {
			mux {
				pins = "gpio74";
				function = "gpio";
			};

			config {
				pins = "gpio74";
				drive-strength = <16>;
				bias-pull-up;
			};
		};
		usb_sw_suspend: usb_sw_suspend {
			mux {
				pins = "gpio135";
				function = "gpio";
			};

			config {
				pins = "gpio135";
				drive-strength = <2>;
				bias-disable;
			};
		};
	};

	nfc_spi_irq_active: nfc_spi_irq_active {
		mux {
			pins = "gpio34";
			function = "gpio";
		};

		config {
			pins = "gpio34";
			drive-strength = <16>;
			bias-pull-up;
		};
	};

	nfc_spi_irq_suspend: nfc_spi_irq_suspend {
		mux {
			pins = "gpio34";
			function = "gpio";
		};

		config {
			pins = "gpio34";
			drive-strength = <2>;
			bias-disable;
		};
	};

	tri_state_key_mux {
		tri_state_key_active: tri_state_key_active {
			mux {
				pins = "gpio77";
				function = "gpio";
			};

			config {
				pins = "gpio77";
				drive-strength = <2>;
				bias-disable;
			};
		};

		tri_state_key_suspend: tri_state_key_suspend {
			mux {
				pins = "gpio77";
				function = "gpio";
			};

			config {
				pins = "gpio77";
				drive-strength = <2>;
				bias-disable;
			};
		};
	};

	tk_mux {
		tk_active: tk_active {
			mux {
				pins = "gpio14", "gpio76", "gpio132";
				function = "gpio";
			};

			config {
				pins = "gpio14", "gpio76", "gpio132";
				drive-strength = <16>;
				bias-pull-up;
			};
		};

		tk_suspend: tk_suspend {
			mux {
				pins = "gpio14", "gpio76", "gpio132";
				function = "gpio";
			};

			config {
				pins = "gpio14", "gpio76", "gpio132";
				drive-strength = <16>;
				bias-pull-up;
			};
		};
	};

	quat_mi2s_mclk {
		quat_mi2s_mclk_sleep: quat_mi2s_mclk_sleep {
			mux {
				pins = "gpio57";
				function = "qua_mi2s";
			};

			config {
				pins = "gpio57";
				drive-strength = <2>;   /* 2 mA */
				bias-pull-down;         /* PULL DOWN */
			};
		};
		quat_mi2s_mclk_active: quat_mi2s_mclk_active {
			mux {
				pins = "gpio57";
				function = "qua_mi2s";
			};

			config {
				pins = "gpio57";
				drive-strength = <8>;   /* 8 mA */
				bias-disable;           /* NO PULL */
			};
		};
	};

	pmx_gpio_switch {
		pmx_gpio_switch_pin_active: pmx_gpio_switch_pin_active {
			mux {
				pins = "gpio97","gpio98","gpio100","gpio115","gpio127","gpio133","gpio136";
				function = "gpio";
			};

			config {
				pins = "gpio97","gpio98","gpio100","gpio115","gpio127","gpio133","gpio136";
				drive-strength = <6>;
				bias-pull-up;
				output-high;
			};
		};

		pmx_gpio_switch_pin_suspend: pmx_gpio_switch_pin_suspend {
			mux {
				pins = "gpio97","gpio98","gpio100","gpio115","gpio127","gpio133","gpio136";
				function = "gpio";
			};

			config {
				pins = "gpio97","gpio98","gpio100","gpio115","gpio127","gpio133","gpio136";
				drive-strength = <6>;
				bias-disable;
				output-high;
			};
		};
	};
};

&ts_active {
	mux {
		pins = "gpio89", "gpio125","gpio49";
	};

	config {
		pins = "gpio89", "gpio125","gpio49";
	};
};

&ts_suspend {
	mux {
		pins = "gpio89", "gpio125","gpio49";
	};

	config {
		pins = "gpio89", "gpio125","gpio49";
	};
};

&i2c_8_active {
	config {
		drive-strength = <16>;
	};
};

&i2c_8_sleep {
	config {
		drive-strength = <16>;
	};
};

&spi_0_active {
	config {
		/delete-property/ bias-disable;
		bias-pull-up;
	};
};

&spi_0_sleep {
	config {
		/delete-property/ bias-disable;
		bias-pull-up;
	};
};

&spi_0_cs_active {
	mux {
		pins = "gpio90";
	};

	config {
		pins = "gpio90";
	};
};

&spi_0_cs_sleep {
	mux {
		pins = "gpio90";
		function = "gpio";
	};

	config {
		pins = "gpio90";
		/delete-property/ bias-pull-up;
		bias-disable;
	};
};

&cdc_reset_active {
	config {
		/delete-property/ bias-pull-down;
		bias-disable;
	};
};

&cam_sensor_rear_active {
	mux {
		pins = "gpio30","gpio39";
	};

	config {
		pins = "gpio30","gpio39";
	};
};

&cam_sensor_rear_suspend {
	mux {
		pins = "gpio30","gpio39";
	};

	config {
		pins = "gpio30","gpio39";
	};
};

&cam_csi2_sensor_active {
	cam_rear_active_cfg {
		pins = "gpio23";
	};
};

&cam_csi2_sensor_suspend{
	cam_rear_suspend_cfg {
		pins = "gpio23";
	};
};

&cam_sensor_front_active {
	mux {
		pins = "gpio23";
	};

	config {
		pins = "gpio23";
	};
};

&cam_sensor_front_suspend {
	mux {
		pins = "gpio23";
	};

	config {
		pins = "gpio23";
	};
};

&rpm_bus {
	rpm-regulator-ldoa14 {
		status = "disabled";
	};

	rpm-regulator-ldoa18 {
		/delete-node/ regulator-l18-pin-ctrl;
	};
};

&pm8994_l3 {
	regulator-min-microvolt = <1100000>;
	regulator-max-microvolt = <1100000>;
	qcom,init-voltage = <1100000>;
};

&pm8994_l13 {
	regulator-min-microvolt = <2950000>;
};

&pm8994_l14 {
	status = "disabled";
};

&pm8994_l17 {
	regulator-min-microvolt = <2600000>;
	regulator-max-microvolt = <2600000>;
	qcom,init-voltage = <2600000>;
};

&pm8994_l18 {
	regulator-min-microvolt = <3300000>;
	regulator-max-microvolt = <3300000>;
	qcom,init-voltage = <3300000>;
};

&pm8994_l22 {
	regulator-min-microvolt = <3000000>;
	qcom,init-voltage = <3000000>;
};

&pm8994_l27 {
	regulator-max-microvolt = <1200000>;
};

&red_led {
	/delete-property/ linux,default-trigger;
	qcom,duty-pcts = [ 00 0E 1C 2A 38 46 54 64 ];
	qcom,start-idx = <0>;
	qcom,idx-len = <8>;
	qcom,pause-lo = <500>;
	qcom,pause-hi = <500>;
	qcom,ramp-step-ms = <50>;
	qcom,lut-flags = <31>; /* loop, ramp up, reverse, pause hi, pause lo */
	qcom,use-blink;
};

&green_led {
	/delete-property/ linux,default-trigger;
	qcom,duty-pcts = [ 00 0E 1C 2A 38 46 54 64 ];
	qcom,start-idx = <8>;
	qcom,idx-len = <8>;
	qcom,pause-lo = <500>;
	qcom,pause-hi = <500>;
	qcom,ramp-step-ms = <50>;
	qcom,lut-flags = <31>; /* loop, ramp up, reverse, pause hi, pause lo */
	qcom,use-blink;
};

&blue_led {
	/delete-property/ linux,default-trigger;
	qcom,duty-pcts = [ 00 0E 1C 2A 38 46 54 64 ];
	qcom,start-idx = <16>;
	qcom,idx-len = <8>;
	qcom,pause-lo = <500>;
	qcom,pause-hi = <500>;
	qcom,ramp-step-ms = <50>;
	qcom,lut-flags = <31>; /* loop, ramp up, reverse, pause hi, pause lo */
	qcom,use-blink;
};
